AUTOSAR XML (schema 4-2-2)
package /STELLANTIS/EPT/ASWCs
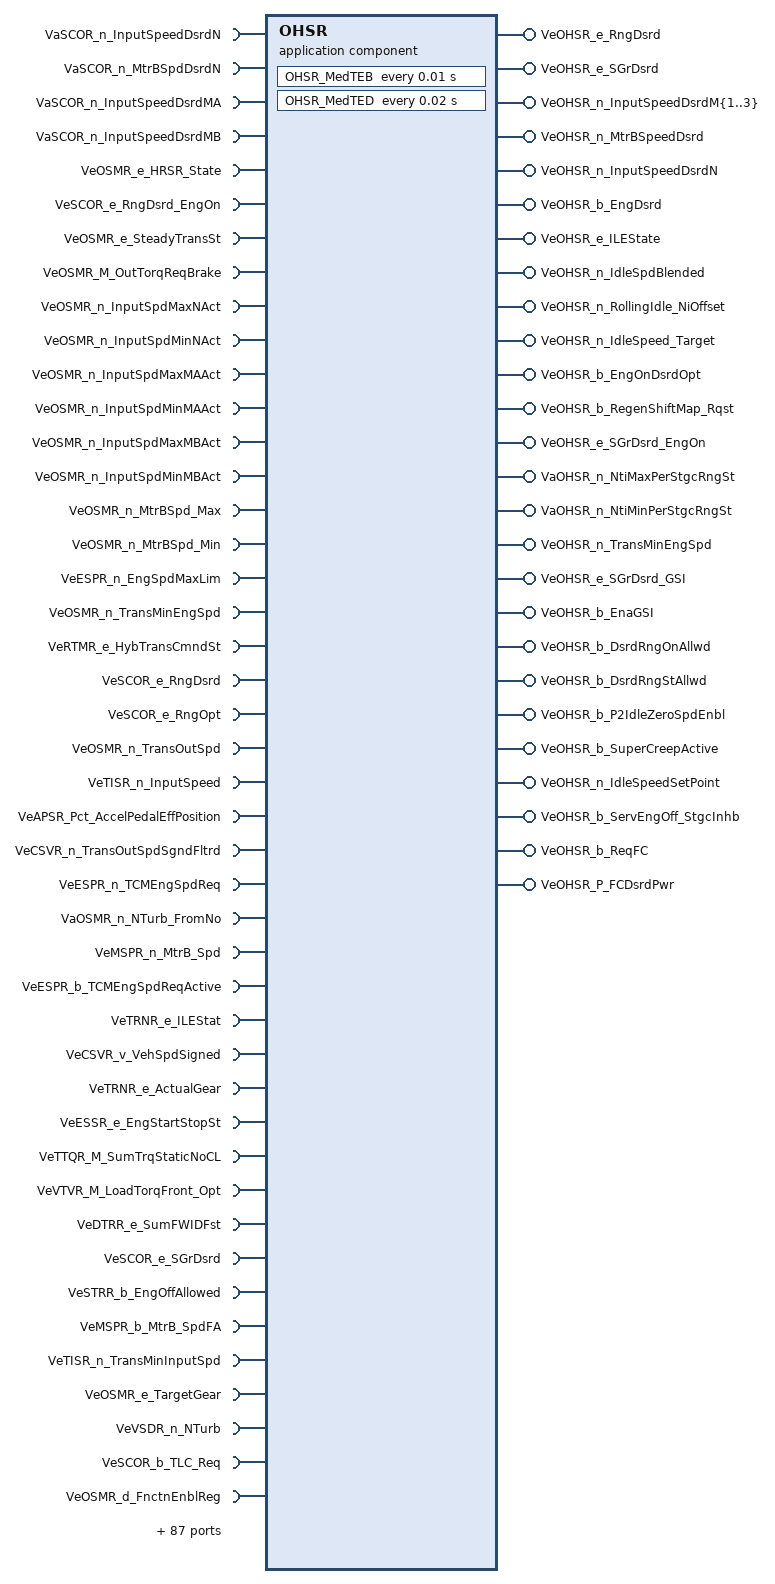
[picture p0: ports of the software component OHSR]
  application sw component type OHSR
    107 x require port:
      VaSCOR_n_InputSpeedDsrdN: nonqueued-receiver-com-spec{data-element=Value, init-value=9 x 0}, required-interface=VaSCOR_n_InputSpeedDsrdN
      VaSCOR_n_MtrBSpdDsrdN: nonqueued-receiver-com-spec{data-element=Value, init-value=9 x 0}, required-interface=VaSCOR_n_MtrBSpdDsrdN
      VaSCOR_n_InputSpeedDsrdMA: nonqueued-receiver-com-spec{data-element=Value, init-value=9 x 0}, required-interface=VaSCOR_n_InputSpeedDsrdMA
      VaSCOR_n_InputSpeedDsrdMB: nonqueued-receiver-com-spec{data-element=Value, init-value=9 x 0}, required-interface=VaSCOR_n_InputSpeedDsrdMB
      VeOSMR_e_HRSR_State: nonqueued-receiver-com-spec{data-element=Value, init-value=CeOSMR_e_N_State}, required-interface=VeOSMR_e_HRSR_State
      VeSCOR_e_RngDsrd_EngOn: nonqueued-receiver-com-spec{data-element=Value, init-value=CeSCOR_e_SG_Neutral}, required-interface=VeSCOR_e_RngDsrd_EngOn
      VeOSMR_e_SteadyTransSt: nonqueued-receiver-com-spec{data-element=Value, init-value=CeOSMR_e_TransSt_Drive}, required-interface=VeOSMR_e_SteadyTransSt
      VeOSMR_M_OutTorqReqBrake: nonqueued-receiver-com-spec{data-element=Value, init-value=0}, required-interface=VeOSMR_M_OutTorqReqBrake
      VeOSMR_n_InputSpdMaxNAct: nonqueued-receiver-com-spec{data-element=Value, init-value=0}, required-interface=VeOSMR_n_InputSpdMaxNAct
      VeOSMR_n_InputSpdMinNAct: nonqueued-receiver-com-spec{data-element=Value, init-value=0}, required-interface=VeOSMR_n_InputSpdMinNAct
      VeOSMR_n_InputSpdMaxMAAct: nonqueued-receiver-com-spec{data-element=Value, init-value=0}, required-interface=VeOSMR_n_InputSpdMaxMAAct
      VeOSMR_n_InputSpdMinMAAct: nonqueued-receiver-com-spec{data-element=Value, init-value=0}, required-interface=VeOSMR_n_InputSpdMinMAAct
      VeOSMR_n_InputSpdMaxMBAct: nonqueued-receiver-com-spec{data-element=Value, init-value=0}, required-interface=VeOSMR_n_InputSpdMaxMBAct
      VeOSMR_n_InputSpdMinMBAct: nonqueued-receiver-com-spec{data-element=Value, init-value=0}, required-interface=VeOSMR_n_InputSpdMinMBAct
      VeOSMR_n_MtrBSpd_Max: nonqueued-receiver-com-spec{data-element=Value, init-value=0}, required-interface=VeOSMR_n_MtrBSpd_Max
      VeOSMR_n_MtrBSpd_Min: nonqueued-receiver-com-spec{data-element=Value, init-value=0}, required-interface=VeOSMR_n_MtrBSpd_Min
      VeESPR_n_EngSpdMaxLim: nonqueued-receiver-com-spec{data-element=Value, init-value=0}, required-interface=VeESPR_n_EngSpdMaxLim
      VeOSMR_n_TransMinEngSpd: nonqueued-receiver-com-spec{data-element=Value, init-value=0}, required-interface=VeOSMR_n_TransMinEngSpd
      VeRTMR_e_HybTransCmndSt: nonqueued-receiver-com-spec{data-element=Value, init-value=CeOHSR_e_RngSel_N}, required-interface=VeRTMR_e_HybTransCmndSt
      VeSCOR_e_RngDsrd: nonqueued-receiver-com-spec{data-element=Value, init-value=CeSCOR_e_SG_Neutral}, required-interface=VeSCOR_e_RngDsrd
      VeSCOR_e_RngOpt: nonqueued-receiver-com-spec{data-element=Value, init-value=CeSCOR_e_SG_Neutral}, required-interface=VeSCOR_e_RngOpt
      VeOSMR_n_TransOutSpd: nonqueued-receiver-com-spec{data-element=Value, init-value=0}, required-interface=VeOSMR_n_TransOutSpd
      VeTISR_n_InputSpeed: nonqueued-receiver-com-spec{data-element=Value, init-value=0}, required-interface=VeTISR_n_InputSpeed
      VeAPSR_Pct_AccelPedalEffPosition: nonqueued-receiver-com-spec{data-element=Value, init-value=0}, required-interface=VeAPSR_Pct_AccelPedalEffPosition
      VeCSVR_n_TransOutSpdSgndFltrd: nonqueued-receiver-com-spec{data-element=Value, init-value=0}, required-interface=VeCSVR_n_TransOutSpdSgndFltrd
      VeESPR_n_TCMEngSpdReq: nonqueued-receiver-com-spec{data-element=Value, init-value=0}, required-interface=VeESPR_n_TCMEngSpdReq
      VaOSMR_n_NTurb_FromNo: nonqueued-receiver-com-spec{data-element=Value, init-value=9 x 0}, required-interface=VaOSMR_n_NTurb_FromNo
      VeMSPR_n_MtrB_Spd: nonqueued-receiver-com-spec{data-element=Value, init-value=0}, required-interface=VeMSPR_n_MtrB_Spd
      VeESPR_b_TCMEngSpdReqActive: nonqueued-receiver-com-spec{data-element=Value, init-value=0}, required-interface=VeESPR_b_TCMEngSpdReqActive
      VeTRNR_e_ILEStat: nonqueued-receiver-com-spec{data-element=Value, init-value=CeHCCR_e_ClInvalid}, required-interface=VeTRNR_e_ILEStat
      VeCSVR_v_VehSpdSigned: nonqueued-receiver-com-spec{data-element=Value, init-value=0}, required-interface=VeCSVR_v_VehSpdSigned
      VeTRNR_e_ActualGear: nonqueued-receiver-com-spec{data-element=Value, init-value=CeTRNR_e_Neutral}, required-interface=VeTRNR_e_ActualGear
      VeESSR_e_EngStartStopSt: nonqueued-receiver-com-spec{data-element=Value, init-value=CeESSR_e_EngOff}, required-interface=VeESSR_e_EngStartStopSt
      VeTTQR_M_SumTrqStaticNoCL: nonqueued-receiver-com-spec{data-element=Value, init-value=0}, required-interface=VeTTQR_M_SumTrqStaticNoCL
      VeVTVR_M_LoadTorqFront_Opt: nonqueued-receiver-com-spec{data-element=Value, init-value=0}, required-interface=VeVTVR_M_LoadTorqFront_Opt
      VeDTRR_e_SumFWIDFst: nonqueued-receiver-com-spec{data-element=Value, init-value=CeDTRR_e_Potential}, required-interface=VeDTRR_e_SumFWIDFst
      VeSCOR_e_SGrDsrd: nonqueued-receiver-com-spec{data-element=Value, init-value=CeSCOR_e_SG_1}, required-interface=VeSCOR_e_SGrDsrd
      VeSTRR_b_EngOffAllowed: nonqueued-receiver-com-spec{data-element=Value, init-value=0}, required-interface=VeSTRR_b_EngOffAllowed
      VeMSPR_b_MtrB_SpdFA: nonqueued-receiver-com-spec{data-element=Value, init-value=0}, required-interface=VeMSPR_b_MtrB_SpdFA
      VeTISR_n_TransMinInputSpd: nonqueued-receiver-com-spec{data-element=Value, init-value=0}, required-interface=VeTISR_n_TransMinInputSpd
      VeOSMR_e_TargetGear: nonqueued-receiver-com-spec{data-element=Value, init-value=CeTRNR_e_Neutral}, required-interface=VeOSMR_e_TargetGear
      VeVSDR_n_NTurb: nonqueued-receiver-com-spec{data-element=Value, init-value=0}, required-interface=VeVSDR_n_NTurb
      VeSCOR_b_TLC_Req: nonqueued-receiver-com-spec{data-element=Value, init-value=0}, required-interface=VeSCOR_b_TLC_Req
      VeOSMR_d_FnctnEnblReg: nonqueued-receiver-com-spec{data-element=Value, init-value=0}, required-interface=VeOSMR_d_FnctnEnblReg
      VeOSMR_e_ActualGear: nonqueued-receiver-com-spec{data-element=Value, init-value=CeTRNR_e_Neutral}, required-interface=VeOSMR_e_ActualGear
      VeSCOR_e_SGrDsrd_EngOn: variation-point={short-label=vpVeSCOR_e_SGrDsrd_EngOn, sw-syscond=1}, nonqueued-receiver-com-spec{data-element=Value, init-value=CeSCOR_e_SG_1}, required-interface=VeSCOR_e_SGrDsrd_EngOn
      VaOSMR_n_NtiMax_N: nonqueued-receiver-com-spec{data-element=Value, init-value=9 x 0}, required-interface=VaOSMR_n_NtiMax_N
      VaOSMR_n_NtiMax_MA: nonqueued-receiver-com-spec{data-element=Value, init-value=9 x 0}, required-interface=VaOSMR_n_NtiMax_MA
      VaOSMR_n_NtiMax_MB: nonqueued-receiver-com-spec{data-element=Value, init-value=9 x 0}, required-interface=VaOSMR_n_NtiMax_MB
      VaOSMR_n_NtiMax_Gr: nonqueued-receiver-com-spec{data-element=Value, init-value=9 x 0}, required-interface=VaOSMR_n_NtiMax_Gr
      VaOSMR_n_NtiMax_EVM: nonqueued-receiver-com-spec{data-element=Value, init-value=9 x 0}, required-interface=VaOSMR_n_NtiMax_EVM
      VaOSMR_n_NtiMax_EVN: nonqueued-receiver-com-spec{data-element=Value, init-value=9 x 0}, required-interface=VaOSMR_n_NtiMax_EVN
      VaOSMR_n_NtiMin_N: nonqueued-receiver-com-spec{data-element=Value, init-value=9 x 0}, required-interface=VaOSMR_n_NtiMin_N
      VaOSMR_n_NtiMin_MA: nonqueued-receiver-com-spec{data-element=Value, init-value=9 x 0}, required-interface=VaOSMR_n_NtiMin_MA
      VaOSMR_n_NtiMin_MB: nonqueued-receiver-com-spec{data-element=Value, init-value=9 x 0}, required-interface=VaOSMR_n_NtiMin_MB
      VaOSMR_n_NtiMin_Gr: nonqueued-receiver-com-spec{data-element=Value, init-value=9 x 0}, required-interface=VaOSMR_n_NtiMin_Gr
      VaOSMR_n_NtiMin_EVM: nonqueued-receiver-com-spec{data-element=Value, init-value=9 x 0}, required-interface=VaOSMR_n_NtiMin_EVM
      VaOSMR_n_NtiMin_EVN: nonqueued-receiver-com-spec{data-element=Value, init-value=9 x 0}, required-interface=VaOSMR_n_NtiMin_EVN
      VeHSER_e_RngSt: nonqueued-receiver-com-spec{data-element=Value, init-value=CeHSER_e_Init}, required-interface=VeHSER_e_RngSt
      VeHSER_e_HTDR_State: nonqueued-receiver-com-spec{data-element=Value, init-value=CeHSER_e_Neut_State}, required-interface=VeHSER_e_HTDR_State
      VeTFTR_T_TransOilTemp: nonqueued-receiver-com-spec{data-element=Value, init-value=0}, required-interface=VeTFTR_T_TransOilTemp
      VeSCOR_Pct_TtlPdlChange: nonqueued-receiver-com-spec{data-element=Value, init-value=0}, required-interface=VeSCOR_Pct_TtlPdlChange
      VeFWDR_e_Tcase_Stat: nonqueued-receiver-com-spec{data-element=Value, init-value=CeFWDR_e_ShiftINProg}, required-interface=VeFWDR_e_Tcase_Stat
      VeVTVR_e_TrqArb: nonqueued-receiver-com-spec{data-element=Value, init-value=CeWTAR_e_ECM_TorqReqst}, required-interface=VeVTVR_e_TrqArb
      VeTRNR_e_TargetGear: nonqueued-receiver-com-spec{data-element=Value, init-value=CeTRNR_e_Neutral}, required-interface=VeTRNR_e_TargetGear
      VeSCOR_b_DsrdRngStAllwd: nonqueued-receiver-com-spec{data-element=Value, init-value=0}, required-interface=VeSCOR_b_DsrdRngStAllwd
      VeESPR_n_EngSpdMinLim: nonqueued-receiver-com-spec{data-element=Value, init-value=0}, required-interface=VeESPR_n_EngSpdMinLim
      VaOSMR_d_FinalAllwdFxdGr: nonqueued-receiver-com-spec{data-element=Value, init-value=6 x 0}, required-interface=VaOSMR_d_FinalAllwdFxdGr
      VaOSMR_d_FinalAllwdDsrd: nonqueued-receiver-com-spec{data-element=Value, init-value=6 x 0}, required-interface=VaOSMR_d_FinalAllwdDsrd
      VeSCOR_b_DsrdRngOnAllwd: nonqueued-receiver-com-spec{data-element=Value, init-value=0}, required-interface=VeSCOR_b_DsrdRngOnAllwd
      VeOSMR_n_InputSpdMaxNTgt: nonqueued-receiver-com-spec{data-element=Value, init-value=0}, required-interface=VeOSMR_n_InputSpdMaxNTgt
      VeOSMR_n_InputSpdMinNTgt: nonqueued-receiver-com-spec{data-element=Value, init-value=0}, required-interface=VeOSMR_n_InputSpdMinNTgt
      VeOSMR_n_InputSpdMaxMATgt: nonqueued-receiver-com-spec{data-element=Value, init-value=0}, required-interface=VeOSMR_n_InputSpdMaxMATgt
      VeOSMR_n_InputSpdMinMATgt: nonqueued-receiver-com-spec{data-element=Value, init-value=0}, required-interface=VeOSMR_n_InputSpdMinMATgt
      VeOSMR_n_InputSpdMaxMBTgt: nonqueued-receiver-com-spec{data-element=Value, init-value=0}, required-interface=VeOSMR_n_InputSpdMaxMBTgt
      VeOSMR_n_InputSpdMinMBTgt: nonqueued-receiver-com-spec{data-element=Value, init-value=0}, required-interface=VeOSMR_n_InputSpdMinMBTgt
      VeRGNR_M_DrvIntndTotBrk_Stgc: nonqueued-receiver-com-spec{data-element=Value, init-value=0}, required-interface=VeRGNR_M_DrvIntndTotBrk_Stgc
      VeRTMR_e_ClutchLrnType: nonqueued-receiver-com-spec{data-element=Value, init-value=CeRTMR_e_Clutch_NoLrn}, required-interface=VeRTMR_e_ClutchLrnType
      VeMSPR_n_P2SpdControl_TgtSpd: nonqueued-receiver-com-spec{data-element=Value, init-value=0}, required-interface=VeMSPR_n_P2SpdControl_TgtSpd
      VeHSER_e_RngEqnSel: nonqueued-receiver-com-spec{data-element=Value, init-value=CeHSER_e_UseNeutralEqn}, required-interface=VeHSER_e_RngEqnSel
      VaOSMR_d_FinalAllwdOpt: nonqueued-receiver-com-spec{data-element=Value, init-value=6 x 0}, required-interface=VaOSMR_d_FinalAllwdOpt
      VeOSMR_b_EngOffAllwdOpt: nonqueued-receiver-com-spec{data-element=Value, init-value=0}, required-interface=VeOSMR_b_EngOffAllwdOpt
      VeCTCR_b_MinCreepEnable_Stgc: nonqueued-receiver-com-spec{data-element=Value, init-value=0}, required-interface=VeCTCR_b_MinCreepEnable_Stgc
      VeBRKR_b_ReqSSC_IdlDst: nonqueued-receiver-com-spec{data-element=Value, init-value=0}, required-interface=VeBRKR_b_ReqSSC_IdlDst
      VeEOCR_b_ColdCtrl_Raw: nonqueued-receiver-com-spec{data-element=Value, init-value=0}, required-interface=VeEOCR_b_ColdCtrl_Raw
      VeCSVR_n_PrimWhlSpdSigned: nonqueued-receiver-com-spec{data-element=Value, init-value=0}, required-interface=VeCSVR_n_PrimWhlSpdSigned
      VeTTQR_e_TCMTrqCntrlMdFst: nonqueued-receiver-com-spec{data-element=Value, init-value=CeTINR_e_None}, required-interface=VeTTQR_e_TCMTrqCntrlMdFst
      VaSCOR_n_C1SlipSpdDsrdN: nonqueued-receiver-com-spec{data-element=Value, init-value=9 x 0}, required-interface=VaSCOR_n_C1SlipSpdDsrdN
      VaSCOR_n_C2SlipSpdDsrdN: nonqueued-receiver-com-spec{data-element=Value, init-value=9 x 0}, required-interface=VaSCOR_n_C2SlipSpdDsrdN
      VeOSMR_d_ManualAllowedN: nonqueued-receiver-com-spec{data-element=Value, init-value=0}, required-interface=VeOSMR_d_ManualAllowedN
      VeOSMR_d_ManualAllowedMA: nonqueued-receiver-com-spec{data-element=Value, init-value=0}, required-interface=VeOSMR_d_ManualAllowedMA
      VeOSMR_d_ManualAllowedMB: nonqueued-receiver-com-spec{data-element=Value, init-value=0}, required-interface=VeOSMR_d_ManualAllowedMB
      VeRTMR_n_TransInputSpd: nonqueued-receiver-com-spec{data-element=Value, init-value=0}, required-interface=VeRTMR_n_TransInputSpd
      VeOSMR_b_ServEngOffReq_Actv: nonqueued-receiver-com-spec{data-element=Value, init-value=0}, required-interface=VeOSMR_b_ServEngOffReq_Actv
      VaSCOR_n_StgcNiMin_N: nonqueued-receiver-com-spec{data-element=Value, init-value=9 x 0}, required-interface=VaSCOR_n_StgcNiMin_N
      VaSCOR_n_StgcNiMin_MA: nonqueued-receiver-com-spec{data-element=Value, init-value=9 x 0}, required-interface=VaSCOR_n_StgcNiMin_MA
      VaSCOR_n_StgcNiMin_MB: nonqueued-receiver-com-spec{data-element=Value, init-value=9 x 0}, required-interface=VaSCOR_n_StgcNiMin_MB
      VeBPCR_Pct_HV_BatPackSOC_Arb: nonqueued-receiver-com-spec{data-element=Value, init-value=0}, required-interface=VeBPCR_Pct_HV_BatPackSOC_Arb
      VeBACR_Pct_TargetSOC_Stgc: nonqueued-receiver-com-spec{data-element=Value, init-value=0}, required-interface=VeBACR_Pct_TargetSOC_Stgc
      VaSCOR_P_EngPwrLoss_N: nonqueued-receiver-com-spec{data-element=Value, init-value=9 x 0}, required-interface=VaSCOR_P_EngPwrLoss_N
      VaSCOR_P_EngPwrLoss_MA: nonqueued-receiver-com-spec{data-element=Value, init-value=9 x 0}, required-interface=VaSCOR_P_EngPwrLoss_MA
      VaSCOR_P_EngPwrLoss_MB: nonqueued-receiver-com-spec{data-element=Value, init-value=9 x 0}, required-interface=VaSCOR_P_EngPwrLoss_MB
      VeICSR_M_EngCL: nonqueued-receiver-com-spec{data-element=Value, init-value=0}, required-interface=VeICSR_M_EngCL
      VeENGR_T_CatalystTemp: nonqueued-receiver-com-spec{data-element=Value, init-value=0}, required-interface=VeENGR_T_CatalystTemp
      VeOSMR_i_DrvPrg_AutoRevMaxType: nonqueued-receiver-com-spec{data-element=Value, init-value=0}, required-interface=VeOSMR_i_DrvPrg_AutoRevMaxType
      VeSCOR_b_ReqFC: nonqueued-receiver-com-spec{data-element=Value, init-value=0}, required-interface=VeSCOR_b_ReqFC
      VeSCOR_P_FCDsrdPwr: nonqueued-receiver-com-spec{data-element=Value, init-value=0}, required-interface=VeSCOR_P_FCDsrdPwr
    28 x provide port:
      VeOHSR_e_RngDsrd: nonqueued-sender-com-spec{data-element=Value, init-value=CeOHSR_e_RngSel_N}, provided-interface=VeOHSR_e_RngDsrd
      VeOHSR_e_SGrDsrd: nonqueued-sender-com-spec{data-element=Value, init-value=CeOHSR_e_SG_Reverse}, provided-interface=VeOHSR_e_SGrDsrd
      VeOHSR_n_InputSpeedDsrdM{1..3}: nonqueued-sender-com-spec{data-element=Value, init-value=0}, provided-interface=VeOHSR_n_InputSpeedDsrdM{1..3}
      VeOHSR_n_MtrBSpeedDsrd: nonqueued-sender-com-spec{data-element=Value, init-value=0}, provided-interface=VeOHSR_n_MtrBSpeedDsrd
      VeOHSR_n_InputSpeedDsrdN: nonqueued-sender-com-spec{data-element=Value, init-value=0}, provided-interface=VeOHSR_n_InputSpeedDsrdN
      VeOHSR_b_EngDsrd: nonqueued-sender-com-spec{data-element=Value, init-value=0}, provided-interface=VeOHSR_b_EngDsrd
      VeOHSR_e_ILEState: nonqueued-sender-com-spec{data-element=Value, init-value=CeOHSR_e_NeutralState}, provided-interface=VeOHSR_e_ILEState
      VeOHSR_n_IdleSpdBlended: nonqueued-sender-com-spec{data-element=Value, init-value=0}, provided-interface=VeOHSR_n_IdleSpdBlended
      VeOHSR_n_RollingIdle_NiOffset: nonqueued-sender-com-spec{data-element=Value, init-value=0}, provided-interface=VeOHSR_n_RollingIdle_NiOffset
      VeOHSR_n_IdleSpeed_Target: nonqueued-sender-com-spec{data-element=Value, init-value=0}, provided-interface=VeOHSR_n_IdleSpeed_Target
      VeOHSR_b_EngOnDsrdOpt: nonqueued-sender-com-spec{data-element=Value, init-value=0}, provided-interface=VeOHSR_b_EngOnDsrdOpt
      VeOHSR_b_RegenShiftMap_Rqst: nonqueued-sender-com-spec{data-element=Value, init-value=0}, provided-interface=VeOHSR_b_RegenShiftMap_Rqst
      VeOHSR_e_SGrDsrd_EngOn: nonqueued-sender-com-spec{data-element=Value, init-value=CeOHSR_e_SG_Reverse}, provided-interface=VeOHSR_e_SGrDsrd_EngOn
      VaOHSR_n_NtiMaxPerStgcRngSt: nonqueued-sender-com-spec{data-element=Value, init-value=6 x 0}, provided-interface=VaOHSR_n_NtiMaxPerStgcRngSt
      VaOHSR_n_NtiMinPerStgcRngSt: nonqueued-sender-com-spec{data-element=Value, init-value=6 x 0}, provided-interface=VaOHSR_n_NtiMinPerStgcRngSt
      VeOHSR_n_TransMinEngSpd: nonqueued-sender-com-spec{data-element=Value, init-value=0}, provided-interface=VeOHSR_n_TransMinEngSpd
      VeOHSR_e_SGrDsrd_GSI: nonqueued-sender-com-spec{data-element=Value, init-value=CeOHSR_e_SG_Reverse}, provided-interface=VeOHSR_e_SGrDsrd_GSI
      VeOHSR_b_EnaGSI: nonqueued-sender-com-spec{data-element=Value, init-value=0}, provided-interface=VeOHSR_b_EnaGSI
      VeOHSR_b_DsrdRngOnAllwd: nonqueued-sender-com-spec{data-element=Value, init-value=0}, provided-interface=VeOHSR_b_DsrdRngOnAllwd
      VeOHSR_b_DsrdRngStAllwd: nonqueued-sender-com-spec{data-element=Value, init-value=0}, provided-interface=VeOHSR_b_DsrdRngStAllwd
      VeOHSR_b_P2IdleZeroSpdEnbl: nonqueued-sender-com-spec{data-element=Value, init-value=0}, provided-interface=VeOHSR_b_P2IdleZeroSpdEnbl
      VeOHSR_b_SuperCreepActive: nonqueued-sender-com-spec{data-element=Value, init-value=0}, provided-interface=VeOHSR_b_SuperCreepActive
      VeOHSR_n_IdleSpeedSetPoint: nonqueued-sender-com-spec{data-element=Value, init-value=0}, provided-interface=VeOHSR_n_IdleSpeedSetPoint
      VeOHSR_b_ServEngOff_StgcInhb: nonqueued-sender-com-spec{data-element=Value, init-value=0}, provided-interface=VeOHSR_b_ServEngOff_StgcInhb
      VeOHSR_b_ReqFC: nonqueued-sender-com-spec{data-element=Value, init-value=0}, provided-interface=VeOHSR_b_ReqFC
      VeOHSR_P_FCDsrdPwr: nonqueued-sender-com-spec{data-element=Value, init-value=0}, provided-interface=VeOHSR_P_FCDsrdPwr
    24 x require port:
      KeOPTR_M_P2ZeroIdle_2Pdl_BrkTrq_LSP: parameter-require-com-spec{init-value=KeOPTR_M_P2ZeroIdle_2Pdl_BrkTrq_LSP_KeOPTR_M_P2ZeroIdle_2Pdl_BrkTrq_LSP:-50, parameter=KeOPTR_M_P2ZeroIdle_2Pdl_BrkTrq_LSP}, required-interface=KeOPTR_M_P2ZeroIdle_2Pdl_BrkTrq_LSP
      KeOPTR_M_P2ZeroIdle_2Pdl_BrkTrq_RSP: parameter-require-com-spec{init-value=KeOPTR_M_P2ZeroIdle_2Pdl_BrkTrq_RSP_KeOPTR_M_P2ZeroIdle_2Pdl_BrkTrq_RSP:-30, parameter=KeOPTR_M_P2ZeroIdle_2Pdl_BrkTrq_RSP}, required-interface=KeOPTR_M_P2ZeroIdle_2Pdl_BrkTrq_RSP
      KeOPTR_M_P2ZeroIdle_BrkTrqMin_RSP_OS: parameter-require-com-spec{init-value=KeOPTR_M_P2ZeroIdle_BrkTrqMin_RSP_OS_KeOPTR_M_P2ZeroIdle_BrkTrqMin_RSP_OS:30, parameter=KeOPTR_M_P2ZeroIdle_BrkTrqMin_RSP_OS}, required-interface=KeOPTR_M_P2ZeroIdle_BrkTrqMin_RSP_OS
      KeOPTR_Pct_P2ZeroIdle_2Pdl_Acl_LSP: parameter-require-com-spec{init-value=KeOPTR_Pct_P2ZeroIdle_2Pdl_Acl_LSP_KeOPTR_Pct_P2ZeroIdle_2Pdl_Acl_LSP:1, parameter=KeOPTR_Pct_P2ZeroIdle_2Pdl_Acl_LSP}, required-interface=KeOPTR_Pct_P2ZeroIdle_2Pdl_Acl_LSP
      KeOPTR_Pct_P2ZeroIdle_2Pdl_Acl_RSP: parameter-require-com-spec{init-value=KeOPTR_Pct_P2ZeroIdle_2Pdl_Acl_RSP_KeOPTR_Pct_P2ZeroIdle_2Pdl_Acl_RSP:0, parameter=KeOPTR_Pct_P2ZeroIdle_2Pdl_Acl_RSP}, required-interface=KeOPTR_Pct_P2ZeroIdle_2Pdl_Acl_RSP
      KeOPTR_n_P2Idle_ZeroRPM: parameter-require-com-spec{init-value=KeOPTR_n_P2Idle_ZeroRPM_KeOPTR_n_P2Idle_ZeroRPM:0, parameter=KeOPTR_n_P2Idle_ZeroRPM}, required-interface=KeOPTR_n_P2Idle_ZeroRPM
      KeOPTR_n_P2MinIdle_TransMinSpd_LSP: parameter-require-com-spec{init-value=KeOPTR_n_P2MinIdle_TransMinSpd_LSP_KeOPTR_n_P2MinIdle_TransMinSpd_LSP:0.25, parameter=KeOPTR_n_P2MinIdle_TransMinSpd_LSP}, required-interface=KeOPTR_n_P2MinIdle_TransMinSpd_LSP
      KeOPTR_n_P2MinIdle_TransMinSpd_RSP: parameter-require-com-spec{init-value=KeOPTR_n_P2MinIdle_TransMinSpd_RSP_KeOPTR_n_P2MinIdle_TransMinSpd_RSP:0.5, parameter=KeOPTR_n_P2MinIdle_TransMinSpd_RSP}, required-interface=KeOPTR_n_P2MinIdle_TransMinSpd_RSP
      KeOPTR_n_P2ZeroIdle_NoMax_LSP: parameter-require-com-spec{init-value=KeOPTR_n_P2ZeroIdle_NoMax_LSP_KeOPTR_n_P2ZeroIdle_NoMax_LSP:20, parameter=KeOPTR_n_P2ZeroIdle_NoMax_LSP}, required-interface=KeOPTR_n_P2ZeroIdle_NoMax_LSP
      KeOPTR_n_P2ZeroIdle_NoMax_RSP: parameter-require-com-spec{init-value=KeOPTR_n_P2ZeroIdle_NoMax_RSP_KeOPTR_n_P2ZeroIdle_NoMax_RSP:25, parameter=KeOPTR_n_P2ZeroIdle_NoMax_RSP}, required-interface=KeOPTR_n_P2ZeroIdle_NoMax_RSP
      KeOPTR_n_RGS_ActivationThreshold: parameter-require-com-spec{init-value=KeOPTR_n_RGS_ActivationThreshold_KeOPTR_n_RGS_ActivationThreshold:500, parameter=KeOPTR_n_RGS_ActivationThreshold}, required-interface=KeOPTR_n_RGS_ActivationThreshold
      KeOPTR_n_RGS_IdleSpd: parameter-require-com-spec{init-value=KeOPTR_n_RGS_IdleSpd_KeOPTR_n_RGS_IdleSpd:950, parameter=KeOPTR_n_RGS_IdleSpd}, required-interface=KeOPTR_n_RGS_IdleSpd
      KeOPTR_t_BrkTrq_TstDer_CutOffT: parameter-require-com-spec{init-value=KeOPTR_t_BrkTrq_TstDer_CutOffT_KeOPTR_t_BrkTrq_TstDer_CutOffT:0.100000001490116, parameter=KeOPTR_t_BrkTrq_TstDer_CutOffT}, required-interface=KeOPTR_t_BrkTrq_TstDer_CutOffT
      KeOPTR_t_DelayTimeToggle: parameter-require-com-spec{init-value=KeOPTR_t_DelayTimeToggle_KeOPTR_t_DelayTimeToggle:10, parameter=KeOPTR_t_DelayTimeToggle}, required-interface=KeOPTR_t_DelayTimeToggle
      KeOPTR_t_RGS_Delay: parameter-require-com-spec{init-value=KeOPTR_t_RGS_Delay_KeOPTR_t_RGS_Delay:1, parameter=KeOPTR_t_RGS_Delay}, required-interface=KeOPTR_t_RGS_Delay
      KeOPTR_t_RGS_DelayTimeNTurb: parameter-require-com-spec{init-value=KeOPTR_t_RGS_DelayTimeNTurb_KeOPTR_t_RGS_DelayTimeNTurb:5, parameter=KeOPTR_t_RGS_DelayTimeNTurb}, required-interface=KeOPTR_t_RGS_DelayTimeNTurb
      KaOPTR_b_RGS_Gears_Sel: parameter-require-com-spec{init-value=KaOPTR_b_RGS_Gears_Sel_KaOPTR_b_RGS_Gears_Sel:[KaOPTR_b_RGS_Gears_Sel_KaOPTR_b_RGS_Gears_Sel_rt_Array_Boolean_13_1:0, KaOPTR_b_RGS_Gears_Sel_KaOPTR_b_RGS_Gears_Sel_rt_Array_Boolean_13_2:0, KaOPTR_b_RGS_Gears_Sel_KaOPTR_b_RGS_Gears_Sel_rt_Array_Boolean_13_3:0, KaOPTR_b_RGS_Gears_Sel_KaOPTR_b_RGS_Gears_Sel_rt_Array_Boolean_13_4:0, KaOPTR_b_RGS_Gears_Sel_KaOPTR_b_RGS_Gears_Sel_rt_Array_Boolean_13_5:0, KaOPTR_b_RGS_Gears_Sel_KaOPTR_b_RGS_Gears_Sel_rt_Array_Boolean_13_6:0, KaOPTR_b_RGS_Gears_Sel_KaOPTR_b_RGS_Gears_Sel_rt_Array_Boolean_13_7:0, KaOPTR_b_RGS_Gears_Sel_KaOPTR_b_RGS_Gears_Sel_rt_Array_Boolean_13_8:0, KaOPTR_b_RGS_Gears_Sel_KaOPTR_b_RGS_Gears_Sel_rt_Array_Boolean_13_9:0, KaOPTR_b_RGS_Gears_Sel_KaOPTR_b_RGS_Gears_Sel_rt_Array_Boolean_13_10:0, KaOPTR_b_RGS_Gears_Sel_KaOPTR_b_RGS_Gears_Sel_rt_Array_Boolean_13_11:0, KaOPTR_b_RGS_Gears_Sel_KaOPTR_b_RGS_Gears_Sel_rt_Array_Boolean_13_12:0, KaOPTR_b_RGS_Gears_Sel_KaOPTR_b_RGS_Gears_Sel_rt_Array_Boolean_13_13:0], parameter=KaOPTR_b_RGS_Gears_Sel}, required-interface=KaOPTR_b_RGS_Gears_Sel
      KaOPTR_b_ZeroRPMAllowPRNDL: parameter-require-com-spec{init-value=KaOPTR_b_ZeroRPMAllowPRNDL_KaOPTR_b_ZeroRPMAllowPRNDL:[KaOPTR_b_ZeroRPMAllowPRNDL_KaOPTR_b_ZeroRPMAllowPRNDL_rt_Array_Boolean_4_1:0, KaOPTR_b_ZeroRPMAllowPRNDL_KaOPTR_b_ZeroRPMAllowPRNDL_rt_Array_Boolean_4_2:0, KaOPTR_b_ZeroRPMAllowPRNDL_KaOPTR_b_ZeroRPMAllowPRNDL_rt_Array_Boolean_4_3:0, KaOPTR_b_ZeroRPMAllowPRNDL_KaOPTR_b_ZeroRPMAllowPRNDL_rt_Array_Boolean_4_4:0], parameter=KaOPTR_b_ZeroRPMAllowPRNDL}, required-interface=KaOPTR_b_ZeroRPMAllowPRNDL
      KaOPTR_b_ZeroRPMAllowTCase: parameter-require-com-spec{init-value=KaOPTR_b_ZeroRPMAllowTCase_KaOPTR_b_ZeroRPMAllowTCase:[KaOPTR_b_ZeroRPMAllowTCase_KaOPTR_b_ZeroRPMAllowTCase_rt_Array_Boolean_8_1:1, KaOPTR_b_ZeroRPMAllowTCase_KaOPTR_b_ZeroRPMAllowTCase_rt_Array_Boolean_8_2:1, KaOPTR_b_ZeroRPMAllowTCase_KaOPTR_b_ZeroRPMAllowTCase_rt_Array_Boolean_8_3:1, KaOPTR_b_ZeroRPMAllowTCase_KaOPTR_b_ZeroRPMAllowTCase_rt_Array_Boolean_8_4:1, KaOPTR_b_ZeroRPMAllowTCase_KaOPTR_b_ZeroRPMAllowTCase_rt_Array_Boolean_8_5:1, KaOPTR_b_ZeroRPMAllowTCase_KaOPTR_b_ZeroRPMAllowTCase_rt_Array_Boolean_8_6:1, KaOPTR_b_ZeroRPMAllowTCase_KaOPTR_b_ZeroRPMAllowTCase_rt_Array_Boolean_8_7:1, KaOPTR_b_ZeroRPMAllowTCase_KaOPTR_b_ZeroRPMAllowTCase_rt_Array_Boolean_8_8:1], parameter=KaOPTR_b_ZeroRPMAllowTCase}, required-interface=KaOPTR_b_ZeroRPMAllowTCase
      KeOPTR_b_RGS_Threshold_Disable: parameter-require-com-spec{init-value=KeOPTR_b_RGS_Threshold_Disable_KeOPTR_b_RGS_Threshold_Disable:0, parameter=KeOPTR_b_RGS_Threshold_Disable}, required-interface=KeOPTR_b_RGS_Threshold_Disable
      KtOPTR_n_P2IdleSpd: parameter-require-com-spec{init-value=10 x 720, parameter=KtOPTR_n_P2IdleSpd}, required-interface=KtOPTR_n_P2IdleSpd
      KxOPTR_n_P2IdleSpd: parameter-require-com-spec{init-value=[-3.3199999332428 0 0.670000016689301 0.839999973773956 1 1.27999997138977 1.66999995708466 2.09999990463257 3.14000010490417 4.71000003814697], parameter=KxOPTR_n_P2IdleSpd}, required-interface=KxOPTR_n_P2IdleSpd
      KtOPTR_M_P2ZeroIdle_BrkTrqThres: parameter-require-com-spec{init-value=[-100 -150 -250 -400 -500 -550], parameter=KtOPTR_M_P2ZeroIdle_BrkTrqThres}, required-interface=KtOPTR_M_P2ZeroIdle_BrkTrqThres
      KxOPTR_M_P2ZeroIdle_BrkTrqThres: parameter-require-com-spec{init-value=[0 100 200 500 1000 1500], parameter=KxOPTR_M_P2ZeroIdle_BrkTrqThres}, required-interface=KxOPTR_M_P2ZeroIdle_BrkTrqThres
    behavior IB_OHSR: data-type-mapping=msADTtoIDTMapping, handle-termination-and-restart=NO-SUPPORT, included-data-type-set=data-type=TeOHSR_e_ActActionBl
      timing event Event_MedTEB: start-on-event=OHSR_MedTEB, period=0.01
      timing event Event_MedTED: start-on-event=OHSR_MedTED, period=0.02
      init event Event_OHSR_ac_Init: start-on-event=OHSR_ac_Init
      init event Event_PwrOn: start-on-event=OHSR_PwrOn
      explicit-inter-runnable-variables:
        17 x data, all with sw-calibration-access=READ-ONLY:
          DsrdRngSt_write_IRV: category=VALUE, type=TeOHSR_e_RngSel, init-value=CeOHSR_e_RngSel_N
          ShftEfftRdctn_write_IRV: category=VALUE, type=Boolean, init-value=0
          ShftEfft_N4H_write_IRV: category=VALUE, type=Boolean, init-value=0
          NTurb_Virt_write_IRV: category=VALUE, type=Float, init-value=0
          VeOHSR_e_ILEState_write_IRV: category=VALUE, type=TeOHSR_e_VLE_DriveStat, init-value=CeOHSR_e_NeutralState
          VeOHSR_n_IdleSpdBlended_write_IRV: category=VALUE, type=Float, init-value=0
          Nti_Max_write_IRV: category=ARRAY, type=rt_Array_Float_54, init-value=54 x 0
          Nti_Min_write_IRV: category=ARRAY, type=rt_Array_Float_54, init-value=54 x 0
          ShiftToN_write_IRV: category=VALUE, type=Boolean, init-value=0
          TransMin_write_IRV: category=VALUE, type=Float, init-value=0
          S2H_write_IRV: category=VALUE, type=Boolean, init-value=0
          PS_write_IRV: category=VALUE, type=Boolean, init-value=0
          EnblTCMReqL_write_IRV: category=VALUE, type=Boolean, init-value=0
          NTurb_ActGr_write_IRV: category=VALUE, type=Float, init-value=0
          dSOC_write_IRV: category=VALUE, type=Float, init-value=0
          StgcMaxGear_NVH_write_IRV: category=ARRAY, type=rt_Array_TeSCOR_e_OptGear_SG_4, init-value=[CeSCOR_e_SG_1, CeSCOR_e_SG_1, CeSCOR_e_SG_1, CeSCOR_e_SG_1]
          RegenShiftMapRqst_write_IRV: category=VALUE, type=Boolean, init-value=0
      4 x runnable:
        OHSR_ac_Init
          data-send-points:
            7 x access:
              OUT_VeOHSR_e_RngDsrd_Value: accessed-variable=VeOHSR_e_RngDsrd.Value
              OUT_VeOHSR_e_SGrDsrd_Value: accessed-variable=VeOHSR_e_SGrDsrd.Value
              OUT_VeOHSR_e_ILEState_Value: accessed-variable=VeOHSR_e_ILEState.Value
              OUT_VeOHSR_e_SGrDsrd_EngOn_Value: accessed-variable=VeOHSR_e_SGrDsrd_EngOn.Value
              OUT_VaOHSR_n_NtiMaxPerStgcRngSt_Value: accessed-variable=VaOHSR_n_NtiMaxPerStgcRngSt.Value
              OUT_VaOHSR_n_NtiMinPerStgcRngSt_Value: accessed-variable=VaOHSR_n_NtiMinPerStgcRngSt.Value
              OUT_VeOHSR_e_SGrDsrd_GSI_Value: accessed-variable=VeOHSR_e_SGrDsrd_GSI.Value
        OHSR_PwrOn
          data-send-points:
            28 x access:
              OUT_VeOHSR_b_EngOnDsrdOpt_Value: accessed-variable=VeOHSR_b_EngOnDsrdOpt.Value
              OUT_VeOHSR_n_InputSpeedDsrdM3_Value: accessed-variable=VeOHSR_n_InputSpeedDsrdM3.Value
              OUT_VeOHSR_n_MtrBSpeedDsrd_Value: accessed-variable=VeOHSR_n_MtrBSpeedDsrd.Value
              OUT_VeOHSR_e_SGrDsrd_Value: accessed-variable=VeOHSR_e_SGrDsrd.Value
              OUT_VeOHSR_n_TransMinEngSpd_Value: accessed-variable=VeOHSR_n_TransMinEngSpd.Value
              OUT_VeOHSR_n_InputSpeedDsrdM1_Value: accessed-variable=VeOHSR_n_InputSpeedDsrdM1.Value
              OUT_VeOHSR_e_SGrDsrd_EngOn_Value: accessed-variable=VeOHSR_e_SGrDsrd_EngOn.Value
              OUT_VeOHSR_n_InputSpeedDsrdM2_Value: accessed-variable=VeOHSR_n_InputSpeedDsrdM2.Value
              OUT_VeOHSR_b_EngDsrd_Value: accessed-variable=VeOHSR_b_EngDsrd.Value
              OUT_VeOHSR_n_InputSpeedDsrdN_Value: accessed-variable=VeOHSR_n_InputSpeedDsrdN.Value
              OUT_VeOHSR_e_RngDsrd_Value: accessed-variable=VeOHSR_e_RngDsrd.Value
              OUT_VeOHSR_n_RollingIdle_NiOffset_Value: accessed-variable=VeOHSR_n_RollingIdle_NiOffset.Value
              OUT_VeOHSR_b_RegenShiftMap_Rqst_Value: accessed-variable=VeOHSR_b_RegenShiftMap_Rqst.Value
              OUT_VeOHSR_e_ILEState_Value: accessed-variable=VeOHSR_e_ILEState.Value
              OUT_VeOHSR_n_IdleSpdBlended_Value: accessed-variable=VeOHSR_n_IdleSpdBlended.Value
              OUT_VeOHSR_n_IdleSpeed_Target_Value: accessed-variable=VeOHSR_n_IdleSpeed_Target.Value
              OUT_VaOHSR_n_NtiMaxPerStgcRngSt_Value: accessed-variable=VaOHSR_n_NtiMaxPerStgcRngSt.Value
              OUT_VaOHSR_n_NtiMinPerStgcRngSt_Value: accessed-variable=VaOHSR_n_NtiMinPerStgcRngSt.Value
              OUT_VeOHSR_e_SGrDsrd_GSI_Value: accessed-variable=VeOHSR_e_SGrDsrd_GSI.Value
              OUT_VeOHSR_b_EnaGSI_Value: accessed-variable=VeOHSR_b_EnaGSI.Value
              OUT_VeOHSR_b_DsrdRngOnAllwd_Value: accessed-variable=VeOHSR_b_DsrdRngOnAllwd.Value
              OUT_VeOHSR_b_DsrdRngStAllwd_Value: accessed-variable=VeOHSR_b_DsrdRngStAllwd.Value
              OUT_VeOHSR_b_P2IdleZeroSpdEnbl_Value: accessed-variable=VeOHSR_b_P2IdleZeroSpdEnbl.Value
              OUT_VeOHSR_b_SuperCreepActive_Value: accessed-variable=VeOHSR_b_SuperCreepActive.Value
              OUT_VeOHSR_n_IdleSpeedSetPoint_Value: accessed-variable=VeOHSR_n_IdleSpeedSetPoint.Value
              OUT_VeOHSR_b_ServEngOff_StgcInhb_Value: accessed-variable=VeOHSR_b_ServEngOff_StgcInhb.Value
              OUT_VeOHSR_P_FCDsrdPwr_Value: accessed-variable=VeOHSR_P_FCDsrdPwr.Value
              OUT_VeOHSR_b_ReqFC_Value: accessed-variable=VeOHSR_b_ReqFC.Value
          written-local-variables:
            17 x access:
              WV_DsrdRngSt_write_IRV: accessed-variable=DsrdRngSt_write_IRV
              WV_EnblTCMReqL_write_IRV: accessed-variable=EnblTCMReqL_write_IRV
              WV_NTurb_ActGr_write_IRV: accessed-variable=NTurb_ActGr_write_IRV
              WV_NTurb_Virt_write_IRV: accessed-variable=NTurb_Virt_write_IRV
              WV_Nti_Max_write_IRV: accessed-variable=Nti_Max_write_IRV
              WV_Nti_Min_write_IRV: accessed-variable=Nti_Min_write_IRV
              WV_PS_write_IRV: accessed-variable=PS_write_IRV
              WV_RegenShiftMapRqst_write_IRV: accessed-variable=RegenShiftMapRqst_write_IRV
              WV_S2H_write_IRV: accessed-variable=S2H_write_IRV
              WV_ShftEfftRdctn_write_IRV: accessed-variable=ShftEfftRdctn_write_IRV
              WV_ShftEfft_N4H_write_IRV: accessed-variable=ShftEfft_N4H_write_IRV
              WV_ShiftToN_write_IRV: accessed-variable=ShiftToN_write_IRV
              WV_StgcMaxGear_NVH_write_IRV: accessed-variable=StgcMaxGear_NVH_write_IRV
              WV_TransMin_write_IRV: accessed-variable=TransMin_write_IRV
              WV_VeOHSR_e_ILEState_write_IRV: accessed-variable=VeOHSR_e_ILEState_write_IRV
              WV_VeOHSR_n_IdleSpdBlended_write_IRV: accessed-variable=VeOHSR_n_IdleSpdBlended_write_IRV
              WV_dSOC_write_IRV: accessed-variable=dSOC_write_IRV
        OHSR_MedTEB
          data-receive-point-by-arguments:
            53 x access:
              IN_VaOSMR_n_NTurb_FromNo_Value: accessed-variable=VaOSMR_n_NTurb_FromNo.Value
              IN_VaOSMR_n_NtiMax_EVM_Value: accessed-variable=VaOSMR_n_NtiMax_EVM.Value
              IN_VaOSMR_n_NtiMax_EVN_Value: accessed-variable=VaOSMR_n_NtiMax_EVN.Value
              IN_VaOSMR_n_NtiMax_Gr_Value: accessed-variable=VaOSMR_n_NtiMax_Gr.Value
              IN_VaOSMR_n_NtiMax_MA_Value: accessed-variable=VaOSMR_n_NtiMax_MA.Value
              IN_VaOSMR_n_NtiMax_MB_Value: accessed-variable=VaOSMR_n_NtiMax_MB.Value
              IN_VaOSMR_n_NtiMax_N_Value: accessed-variable=VaOSMR_n_NtiMax_N.Value
              IN_VaOSMR_n_NtiMin_EVM_Value: accessed-variable=VaOSMR_n_NtiMin_EVM.Value
              IN_VaOSMR_n_NtiMin_EVN_Value: accessed-variable=VaOSMR_n_NtiMin_EVN.Value
              IN_VaOSMR_n_NtiMin_Gr_Value: accessed-variable=VaOSMR_n_NtiMin_Gr.Value
              IN_VaOSMR_n_NtiMin_MA_Value: accessed-variable=VaOSMR_n_NtiMin_MA.Value
              IN_VaOSMR_n_NtiMin_MB_Value: accessed-variable=VaOSMR_n_NtiMin_MB.Value
              IN_VaOSMR_n_NtiMin_N_Value: accessed-variable=VaOSMR_n_NtiMin_N.Value
              IN_VaSCOR_n_InputSpeedDsrdMA_Value: accessed-variable=VaSCOR_n_InputSpeedDsrdMA.Value
              IN_VaSCOR_n_InputSpeedDsrdMB_Value: accessed-variable=VaSCOR_n_InputSpeedDsrdMB.Value
              IN_VeAPSR_Pct_AccelPedalEffPosition_Value: accessed-variable=VeAPSR_Pct_AccelPedalEffPosition.Value
              IN_VeBACR_Pct_TargetSOC_Stgc_Value: accessed-variable=VeBACR_Pct_TargetSOC_Stgc.Value
              IN_VeBPCR_Pct_HV_BatPackSOC_Arb_Value: accessed-variable=VeBPCR_Pct_HV_BatPackSOC_Arb.Value
              IN_VeBRKR_b_ReqSSC_IdlDst_Value: accessed-variable=VeBRKR_b_ReqSSC_IdlDst.Value
              IN_VeCSVR_n_PrimWhlSpdSigned_Value: accessed-variable=VeCSVR_n_PrimWhlSpdSigned.Value
              IN_VeCSVR_n_TransOutSpdSgndFltrd_Value: accessed-variable=VeCSVR_n_TransOutSpdSgndFltrd.Value
              IN_VeCSVR_v_VehSpdSigned_Value: accessed-variable=VeCSVR_v_VehSpdSigned.Value
              IN_VeCTCR_b_MinCreepEnable_Stgc_Value: accessed-variable=VeCTCR_b_MinCreepEnable_Stgc.Value
              IN_VeDTRR_e_SumFWIDFst_Value: accessed-variable=VeDTRR_e_SumFWIDFst.Value
              IN_VeEOCR_b_ColdCtrl_Raw_Value: accessed-variable=VeEOCR_b_ColdCtrl_Raw.Value
              IN_VeESSR_e_EngStartStopSt_Value: accessed-variable=VeESSR_e_EngStartStopSt.Value
              IN_VeFWDR_e_Tcase_Stat_Value: accessed-variable=VeFWDR_e_Tcase_Stat.Value
              IN_VeHSER_e_HTDR_State_Value: accessed-variable=VeHSER_e_HTDR_State.Value
              IN_VeHSER_e_RngEqnSel_Value: accessed-variable=VeHSER_e_RngEqnSel.Value
              IN_VeHSER_e_RngSt_Value: accessed-variable=VeHSER_e_RngSt.Value
              IN_VeICSR_M_EngCL_Value: accessed-variable=VeICSR_M_EngCL.Value
              IN_VeMSPR_b_MtrB_SpdFA_Value: accessed-variable=VeMSPR_b_MtrB_SpdFA.Value
              IN_VeMSPR_n_MtrB_Spd_Value: accessed-variable=VeMSPR_n_MtrB_Spd.Value
              IN_VeMSPR_n_P2SpdControl_TgtSpd_Value: accessed-variable=VeMSPR_n_P2SpdControl_TgtSpd.Value
              IN_VeOSMR_M_OutTorqReqBrake_Value: accessed-variable=VeOSMR_M_OutTorqReqBrake.Value
              IN_VeOSMR_d_FnctnEnblReg_Value: accessed-variable=VeOSMR_d_FnctnEnblReg.Value
              IN_VeOSMR_e_ActualGear_Value: accessed-variable=VeOSMR_e_ActualGear.Value
              IN_VeOSMR_e_HRSR_State_Value: accessed-variable=VeOSMR_e_HRSR_State.Value
              IN_VeOSMR_e_SteadyTransSt_Value: accessed-variable=VeOSMR_e_SteadyTransSt.Value
              IN_VeOSMR_e_TargetGear_Value: accessed-variable=VeOSMR_e_TargetGear.Value
              IN_VeOSMR_n_TransMinEngSpd_Value: accessed-variable=VeOSMR_n_TransMinEngSpd.Value
              IN_VeRGNR_M_DrvIntndTotBrk_Stgc_Value: accessed-variable=VeRGNR_M_DrvIntndTotBrk_Stgc.Value
              IN_VeTFTR_T_TransOilTemp_Value: accessed-variable=VeTFTR_T_TransOilTemp.Value
              IN_VeTISR_n_InputSpeed_Value: accessed-variable=VeTISR_n_InputSpeed.Value
              IN_VeTISR_n_TransMinInputSpd_Value: accessed-variable=VeTISR_n_TransMinInputSpd.Value
              IN_VeTRNR_e_ActualGear_Value: accessed-variable=VeTRNR_e_ActualGear.Value
              IN_VeTRNR_e_ILEStat_Value: accessed-variable=VeTRNR_e_ILEStat.Value
              IN_VeTRNR_e_TargetGear_Value: accessed-variable=VeTRNR_e_TargetGear.Value
              IN_VeTTQR_M_SumTrqStaticNoCL_Value: accessed-variable=VeTTQR_M_SumTrqStaticNoCL.Value
              IN_VeTTQR_e_TCMTrqCntrlMdFst_Value: accessed-variable=VeTTQR_e_TCMTrqCntrlMdFst.Value
              IN_VeVSDR_n_NTurb_Value: accessed-variable=VeVSDR_n_NTurb.Value
              IN_VeVTVR_M_LoadTorqFront_Opt_Value: accessed-variable=VeVTVR_M_LoadTorqFront_Opt.Value
              IN_VeVTVR_e_TrqArb_Value: accessed-variable=VeVTVR_e_TrqArb.Value
          data-send-points:
            7 x access:
              OUT_VeOHSR_e_ILEState_Value: accessed-variable=VeOHSR_e_ILEState.Value
              OUT_VeOHSR_n_IdleSpdBlended_Value: accessed-variable=VeOHSR_n_IdleSpdBlended.Value
              OUT_VeOHSR_n_RollingIdle_NiOffset_Value: accessed-variable=VeOHSR_n_RollingIdle_NiOffset.Value
              OUT_VeOHSR_n_IdleSpeed_Target_Value: accessed-variable=VeOHSR_n_IdleSpeed_Target.Value
              OUT_VeOHSR_b_P2IdleZeroSpdEnbl_Value: accessed-variable=VeOHSR_b_P2IdleZeroSpdEnbl.Value
              OUT_VeOHSR_b_SuperCreepActive_Value: accessed-variable=VeOHSR_b_SuperCreepActive.Value
              OUT_VeOHSR_n_IdleSpeedSetPoint_Value: accessed-variable=VeOHSR_n_IdleSpeedSetPoint.Value
          24 x parameter access:
            CALPRM_KaOPTR_b_RGS_Gears_Sel_KaOPTR_b_RGS_Gears_Sel: accessed-parameter=KaOPTR_b_RGS_Gears_Sel.KaOPTR_b_RGS_Gears_Sel
            CALPRM_KaOPTR_b_ZeroRPMAllowPRNDL_KaOPTR_b_ZeroRPMAllowPRNDL: accessed-parameter=KaOPTR_b_ZeroRPMAllowPRNDL.KaOPTR_b_ZeroRPMAllowPRNDL
            CALPRM_KaOPTR_b_ZeroRPMAllowTCase_KaOPTR_b_ZeroRPMAllowTCase: accessed-parameter=KaOPTR_b_ZeroRPMAllowTCase.KaOPTR_b_ZeroRPMAllowTCase
            CALPRM_KeOPTR_M_P2ZeroIdle_2Pdl_BrkTrq_LSP_KeOPTR_M_P2ZeroIdle_2Pdl_BrkTrq_LSP: accessed-parameter=KeOPTR_M_P2ZeroIdle_2Pdl_BrkTrq_LSP.KeOPTR_M_P2ZeroIdle_2Pdl_BrkTrq_LSP
            CALPRM_KeOPTR_M_P2ZeroIdle_2Pdl_BrkTrq_RSP_KeOPTR_M_P2ZeroIdle_2Pdl_BrkTrq_RSP: accessed-parameter=KeOPTR_M_P2ZeroIdle_2Pdl_BrkTrq_RSP.KeOPTR_M_P2ZeroIdle_2Pdl_BrkTrq_RSP
            CALPRM_KeOPTR_M_P2ZeroIdle_BrkTrqMin_RSP_OS_KeOPTR_M_P2ZeroIdle_BrkTrqMin_RSP_OS: accessed-parameter=KeOPTR_M_P2ZeroIdle_BrkTrqMin_RSP_OS.KeOPTR_M_P2ZeroIdle_BrkTrqMin_RSP_OS
            CALPRM_KeOPTR_Pct_P2ZeroIdle_2Pdl_Acl_LSP_KeOPTR_Pct_P2ZeroIdle_2Pdl_Acl_LSP: accessed-parameter=KeOPTR_Pct_P2ZeroIdle_2Pdl_Acl_LSP.KeOPTR_Pct_P2ZeroIdle_2Pdl_Acl_LSP
            CALPRM_KeOPTR_Pct_P2ZeroIdle_2Pdl_Acl_RSP_KeOPTR_Pct_P2ZeroIdle_2Pdl_Acl_RSP: accessed-parameter=KeOPTR_Pct_P2ZeroIdle_2Pdl_Acl_RSP.KeOPTR_Pct_P2ZeroIdle_2Pdl_Acl_RSP
            CALPRM_KeOPTR_b_RGS_Threshold_Disable_KeOPTR_b_RGS_Threshold_Disable: accessed-parameter=KeOPTR_b_RGS_Threshold_Disable.KeOPTR_b_RGS_Threshold_Disable
            CALPRM_KeOPTR_n_P2Idle_ZeroRPM_KeOPTR_n_P2Idle_ZeroRPM: accessed-parameter=KeOPTR_n_P2Idle_ZeroRPM.KeOPTR_n_P2Idle_ZeroRPM
            CALPRM_KeOPTR_n_P2MinIdle_TransMinSpd_LSP_KeOPTR_n_P2MinIdle_TransMinSpd_LSP: accessed-parameter=KeOPTR_n_P2MinIdle_TransMinSpd_LSP.KeOPTR_n_P2MinIdle_TransMinSpd_LSP
            CALPRM_KeOPTR_n_P2MinIdle_TransMinSpd_RSP_KeOPTR_n_P2MinIdle_TransMinSpd_RSP: accessed-parameter=KeOPTR_n_P2MinIdle_TransMinSpd_RSP.KeOPTR_n_P2MinIdle_TransMinSpd_RSP
            CALPRM_KeOPTR_n_P2ZeroIdle_NoMax_LSP_KeOPTR_n_P2ZeroIdle_NoMax_LSP: accessed-parameter=KeOPTR_n_P2ZeroIdle_NoMax_LSP.KeOPTR_n_P2ZeroIdle_NoMax_LSP
            CALPRM_KeOPTR_n_P2ZeroIdle_NoMax_RSP_KeOPTR_n_P2ZeroIdle_NoMax_RSP: accessed-parameter=KeOPTR_n_P2ZeroIdle_NoMax_RSP.KeOPTR_n_P2ZeroIdle_NoMax_RSP
            CALPRM_KeOPTR_n_RGS_ActivationThreshold_KeOPTR_n_RGS_ActivationThreshold: accessed-parameter=KeOPTR_n_RGS_ActivationThreshold.KeOPTR_n_RGS_ActivationThreshold
            CALPRM_KeOPTR_n_RGS_IdleSpd_KeOPTR_n_RGS_IdleSpd: accessed-parameter=KeOPTR_n_RGS_IdleSpd.KeOPTR_n_RGS_IdleSpd
            CALPRM_KeOPTR_t_BrkTrq_TstDer_CutOffT_KeOPTR_t_BrkTrq_TstDer_CutOffT: accessed-parameter=KeOPTR_t_BrkTrq_TstDer_CutOffT.KeOPTR_t_BrkTrq_TstDer_CutOffT
            CALPRM_KeOPTR_t_DelayTimeToggle_KeOPTR_t_DelayTimeToggle: accessed-parameter=KeOPTR_t_DelayTimeToggle.KeOPTR_t_DelayTimeToggle
            CALPRM_KeOPTR_t_RGS_Delay_KeOPTR_t_RGS_Delay: accessed-parameter=KeOPTR_t_RGS_Delay.KeOPTR_t_RGS_Delay
            CALPRM_KeOPTR_t_RGS_DelayTimeNTurb_KeOPTR_t_RGS_DelayTimeNTurb: accessed-parameter=KeOPTR_t_RGS_DelayTimeNTurb.KeOPTR_t_RGS_DelayTimeNTurb
            CALPRM_KtOPTR_M_P2ZeroIdle_BrkTrqThres_KtOPTR_M_P2ZeroIdle_BrkTrqThres: accessed-parameter=KtOPTR_M_P2ZeroIdle_BrkTrqThres.KtOPTR_M_P2ZeroIdle_BrkTrqThres
            CALPRM_KtOPTR_n_P2IdleSpd_KtOPTR_n_P2IdleSpd: accessed-parameter=KtOPTR_n_P2IdleSpd.KtOPTR_n_P2IdleSpd
            CALPRM_KxOPTR_M_P2ZeroIdle_BrkTrqThres_KxOPTR_M_P2ZeroIdle_BrkTrqThres: accessed-parameter=KxOPTR_M_P2ZeroIdle_BrkTrqThres.KxOPTR_M_P2ZeroIdle_BrkTrqThres
            CALPRM_KxOPTR_n_P2IdleSpd_KxOPTR_n_P2IdleSpd: accessed-parameter=KxOPTR_n_P2IdleSpd.KxOPTR_n_P2IdleSpd
          read-local-variables:
            access RV_DsrdRngSt_write_IRV: accessed-variable=DsrdRngSt_write_IRV
            access RV_ShftEfftRdctn_write_IRV: accessed-variable=ShftEfftRdctn_write_IRV
            access RV_ShftEfft_N4H_write_IRV: accessed-variable=ShftEfft_N4H_write_IRV
          written-local-variables:
            14 x access:
              WV_EnblTCMReqL_write_IRV: accessed-variable=EnblTCMReqL_write_IRV
              WV_NTurb_ActGr_write_IRV: accessed-variable=NTurb_ActGr_write_IRV
              WV_NTurb_Virt_write_IRV: accessed-variable=NTurb_Virt_write_IRV
              WV_Nti_Max_write_IRV: accessed-variable=Nti_Max_write_IRV
              WV_Nti_Min_write_IRV: accessed-variable=Nti_Min_write_IRV
              WV_PS_write_IRV: accessed-variable=PS_write_IRV
              WV_RegenShiftMapRqst_write_IRV: accessed-variable=RegenShiftMapRqst_write_IRV
              WV_S2H_write_IRV: accessed-variable=S2H_write_IRV
              WV_ShiftToN_write_IRV: accessed-variable=ShiftToN_write_IRV
              WV_StgcMaxGear_NVH_write_IRV: accessed-variable=StgcMaxGear_NVH_write_IRV
              WV_TransMin_write_IRV: accessed-variable=TransMin_write_IRV
              WV_VeOHSR_e_ILEState_write_IRV: accessed-variable=VeOHSR_e_ILEState_write_IRV
              WV_VeOHSR_n_IdleSpdBlended_write_IRV: accessed-variable=VeOHSR_n_IdleSpdBlended_write_IRV
              WV_dSOC_write_IRV: accessed-variable=dSOC_write_IRV
        OHSR_MedTED
          data-receive-point-by-arguments:
            80 x access:
              IN_VaOSMR_d_FinalAllwdDsrd_Value: accessed-variable=VaOSMR_d_FinalAllwdDsrd.Value
              IN_VaOSMR_d_FinalAllwdFxdGr_Value: accessed-variable=VaOSMR_d_FinalAllwdFxdGr.Value
              IN_VaOSMR_d_FinalAllwdOpt_Value: accessed-variable=VaOSMR_d_FinalAllwdOpt.Value
              IN_VaOSMR_n_NTurb_FromNo_Value: accessed-variable=VaOSMR_n_NTurb_FromNo.Value
              IN_VaSCOR_P_EngPwrLoss_MA_Value: accessed-variable=VaSCOR_P_EngPwrLoss_MA.Value
              IN_VaSCOR_P_EngPwrLoss_MB_Value: accessed-variable=VaSCOR_P_EngPwrLoss_MB.Value
              IN_VaSCOR_P_EngPwrLoss_N_Value: accessed-variable=VaSCOR_P_EngPwrLoss_N.Value
              IN_VaSCOR_n_C1SlipSpdDsrdN_Value: accessed-variable=VaSCOR_n_C1SlipSpdDsrdN.Value
              IN_VaSCOR_n_C2SlipSpdDsrdN_Value: accessed-variable=VaSCOR_n_C2SlipSpdDsrdN.Value
              IN_VaSCOR_n_InputSpeedDsrdMA_Value: accessed-variable=VaSCOR_n_InputSpeedDsrdMA.Value
              IN_VaSCOR_n_InputSpeedDsrdMB_Value: accessed-variable=VaSCOR_n_InputSpeedDsrdMB.Value
              IN_VaSCOR_n_InputSpeedDsrdN_Value: accessed-variable=VaSCOR_n_InputSpeedDsrdN.Value
              IN_VaSCOR_n_MtrBSpdDsrdN_Value: accessed-variable=VaSCOR_n_MtrBSpdDsrdN.Value
              IN_VaSCOR_n_StgcNiMin_MA_Value: accessed-variable=VaSCOR_n_StgcNiMin_MA.Value
              IN_VaSCOR_n_StgcNiMin_MB_Value: accessed-variable=VaSCOR_n_StgcNiMin_MB.Value
              IN_VaSCOR_n_StgcNiMin_N_Value: accessed-variable=VaSCOR_n_StgcNiMin_N.Value
              IN_VeAPSR_Pct_AccelPedalEffPosition_Value: accessed-variable=VeAPSR_Pct_AccelPedalEffPosition.Value
              IN_VeBPCR_Pct_HV_BatPackSOC_Arb_Value: accessed-variable=VeBPCR_Pct_HV_BatPackSOC_Arb.Value
              IN_VeDTRR_e_SumFWIDFst_Value: accessed-variable=VeDTRR_e_SumFWIDFst.Value
              IN_VeENGR_T_CatalystTemp_Value: accessed-variable=VeENGR_T_CatalystTemp.Value
              IN_VeEOCR_b_ColdCtrl_Raw_Value: accessed-variable=VeEOCR_b_ColdCtrl_Raw.Value
              IN_VeESPR_b_TCMEngSpdReqActive_Value: accessed-variable=VeESPR_b_TCMEngSpdReqActive.Value
              IN_VeESPR_n_EngSpdMaxLim_Value: accessed-variable=VeESPR_n_EngSpdMaxLim.Value
              IN_VeESPR_n_EngSpdMinLim_Value: accessed-variable=VeESPR_n_EngSpdMinLim.Value
              IN_VeESPR_n_TCMEngSpdReq_Value: accessed-variable=VeESPR_n_TCMEngSpdReq.Value
              IN_VeESSR_e_EngStartStopSt_Value: accessed-variable=VeESSR_e_EngStartStopSt.Value
              IN_VeFWDR_e_Tcase_Stat_Value: accessed-variable=VeFWDR_e_Tcase_Stat.Value
              IN_VeHSER_e_RngEqnSel_Value: accessed-variable=VeHSER_e_RngEqnSel.Value
              IN_VeHSER_e_RngSt_Value: accessed-variable=VeHSER_e_RngSt.Value
              IN_VeMSPR_n_MtrB_Spd_Value: accessed-variable=VeMSPR_n_MtrB_Spd.Value
              IN_VeMSPR_n_P2SpdControl_TgtSpd_Value: accessed-variable=VeMSPR_n_P2SpdControl_TgtSpd.Value
              IN_VeOSMR_b_EngOffAllwdOpt_Value: accessed-variable=VeOSMR_b_EngOffAllwdOpt.Value
              IN_VeOSMR_b_ServEngOffReq_Actv_Value: accessed-variable=VeOSMR_b_ServEngOffReq_Actv.Value
              IN_VeOSMR_d_FnctnEnblReg_Value: accessed-variable=VeOSMR_d_FnctnEnblReg.Value
              IN_VeOSMR_d_ManualAllowedMA_Value: accessed-variable=VeOSMR_d_ManualAllowedMA.Value
              IN_VeOSMR_d_ManualAllowedMB_Value: accessed-variable=VeOSMR_d_ManualAllowedMB.Value
              IN_VeOSMR_d_ManualAllowedN_Value: accessed-variable=VeOSMR_d_ManualAllowedN.Value
              IN_VeOSMR_e_ActualGear_Value: accessed-variable=VeOSMR_e_ActualGear.Value
              IN_VeOSMR_e_SteadyTransSt_Value: accessed-variable=VeOSMR_e_SteadyTransSt.Value
              IN_VeOSMR_e_TargetGear_Value: accessed-variable=VeOSMR_e_TargetGear.Value
              IN_VeOSMR_i_DrvPrg_AutoRevMaxType_Value: accessed-variable=VeOSMR_i_DrvPrg_AutoRevMaxType.Value
              IN_VeOSMR_n_InputSpdMaxMAAct_Value: accessed-variable=VeOSMR_n_InputSpdMaxMAAct.Value
              IN_VeOSMR_n_InputSpdMaxMATgt_Value: accessed-variable=VeOSMR_n_InputSpdMaxMATgt.Value
              IN_VeOSMR_n_InputSpdMaxMBAct_Value: accessed-variable=VeOSMR_n_InputSpdMaxMBAct.Value
              IN_VeOSMR_n_InputSpdMaxMBTgt_Value: accessed-variable=VeOSMR_n_InputSpdMaxMBTgt.Value
              IN_VeOSMR_n_InputSpdMaxNAct_Value: accessed-variable=VeOSMR_n_InputSpdMaxNAct.Value
              IN_VeOSMR_n_InputSpdMaxNTgt_Value: accessed-variable=VeOSMR_n_InputSpdMaxNTgt.Value
              IN_VeOSMR_n_InputSpdMinMAAct_Value: accessed-variable=VeOSMR_n_InputSpdMinMAAct.Value
              IN_VeOSMR_n_InputSpdMinMATgt_Value: accessed-variable=VeOSMR_n_InputSpdMinMATgt.Value
              IN_VeOSMR_n_InputSpdMinMBAct_Value: accessed-variable=VeOSMR_n_InputSpdMinMBAct.Value
              IN_VeOSMR_n_InputSpdMinMBTgt_Value: accessed-variable=VeOSMR_n_InputSpdMinMBTgt.Value
              IN_VeOSMR_n_InputSpdMinNAct_Value: accessed-variable=VeOSMR_n_InputSpdMinNAct.Value
              IN_VeOSMR_n_InputSpdMinNTgt_Value: accessed-variable=VeOSMR_n_InputSpdMinNTgt.Value
              IN_VeOSMR_n_MtrBSpd_Max_Value: accessed-variable=VeOSMR_n_MtrBSpd_Max.Value
              IN_VeOSMR_n_MtrBSpd_Min_Value: accessed-variable=VeOSMR_n_MtrBSpd_Min.Value
              IN_VeOSMR_n_TransMinEngSpd_Value: accessed-variable=VeOSMR_n_TransMinEngSpd.Value
              IN_VeOSMR_n_TransOutSpd_Value: accessed-variable=VeOSMR_n_TransOutSpd.Value
              IN_VeRTMR_e_ClutchLrnType_Value: accessed-variable=VeRTMR_e_ClutchLrnType.Value
              IN_VeRTMR_e_HybTransCmndSt_Value: accessed-variable=VeRTMR_e_HybTransCmndSt.Value
              IN_VeRTMR_n_TransInputSpd_Value: accessed-variable=VeRTMR_n_TransInputSpd.Value
              IN_VeSCOR_P_FCDsrdPwr_Value: accessed-variable=VeSCOR_P_FCDsrdPwr.Value
              IN_VeSCOR_Pct_TtlPdlChange_Value: accessed-variable=VeSCOR_Pct_TtlPdlChange.Value
              IN_VeSCOR_b_DsrdRngOnAllwd_Value: accessed-variable=VeSCOR_b_DsrdRngOnAllwd.Value
              IN_VeSCOR_b_DsrdRngStAllwd_Value: accessed-variable=VeSCOR_b_DsrdRngStAllwd.Value
              IN_VeSCOR_b_ReqFC_Value: accessed-variable=VeSCOR_b_ReqFC.Value
              IN_VeSCOR_b_TLC_Req_Value: accessed-variable=VeSCOR_b_TLC_Req.Value
              IN_VeSCOR_e_RngDsrd_Value: accessed-variable=VeSCOR_e_RngDsrd.Value
              IN_VeSCOR_e_RngDsrd_EngOn_Value: accessed-variable=VeSCOR_e_RngDsrd_EngOn.Value
              IN_VeSCOR_e_RngOpt_Value: accessed-variable=VeSCOR_e_RngOpt.Value
              IN_VeSCOR_e_SGrDsrd_Value: accessed-variable=VeSCOR_e_SGrDsrd.Value
              IN_VeSCOR_e_SGrDsrd_EngOn_Value: accessed-variable=VeSCOR_e_SGrDsrd_EngOn.Value, variation-point={short-label=vpIN_VeSCOR_e_SGrDsrd_EngOn_Value, sw-syscond=1}
              IN_VeSTRR_b_EngOffAllowed_Value: accessed-variable=VeSTRR_b_EngOffAllowed.Value
              IN_VeTFTR_T_TransOilTemp_Value: accessed-variable=VeTFTR_T_TransOilTemp.Value
              IN_VeTISR_n_InputSpeed_Value: accessed-variable=VeTISR_n_InputSpeed.Value
              IN_VeTISR_n_TransMinInputSpd_Value: accessed-variable=VeTISR_n_TransMinInputSpd.Value
              IN_VeTRNR_e_ActualGear_Value: accessed-variable=VeTRNR_e_ActualGear.Value
              IN_VeTRNR_e_TargetGear_Value: accessed-variable=VeTRNR_e_TargetGear.Value
              IN_VeVSDR_n_NTurb_Value: accessed-variable=VeVSDR_n_NTurb.Value
              IN_VeVTVR_M_LoadTorqFront_Opt_Value: accessed-variable=VeVTVR_M_LoadTorqFront_Opt.Value
              IN_VeVTVR_e_TrqArb_Value: accessed-variable=VeVTVR_e_TrqArb.Value
          data-send-points:
            21 x access:
              OUT_VeOHSR_b_EngOnDsrdOpt_Value: accessed-variable=VeOHSR_b_EngOnDsrdOpt.Value
              OUT_VeOHSR_e_SGrDsrd_Value: accessed-variable=VeOHSR_e_SGrDsrd.Value
              OUT_VeOHSR_e_SGrDsrd_EngOn_Value: accessed-variable=VeOHSR_e_SGrDsrd_EngOn.Value
              OUT_VeOHSR_b_EngDsrd_Value: accessed-variable=VeOHSR_b_EngDsrd.Value
              OUT_VaOHSR_n_NtiMaxPerStgcRngSt_Value: accessed-variable=VaOHSR_n_NtiMaxPerStgcRngSt.Value
              OUT_VaOHSR_n_NtiMinPerStgcRngSt_Value: accessed-variable=VaOHSR_n_NtiMinPerStgcRngSt.Value
              OUT_VeOHSR_e_SGrDsrd_GSI_Value: accessed-variable=VeOHSR_e_SGrDsrd_GSI.Value
              OUT_VeOHSR_b_EnaGSI_Value: accessed-variable=VeOHSR_b_EnaGSI.Value
              OUT_VeOHSR_b_ServEngOff_StgcInhb_Value: accessed-variable=VeOHSR_b_ServEngOff_StgcInhb.Value
              OUT_VeOHSR_n_InputSpeedDsrdM3_Value: accessed-variable=VeOHSR_n_InputSpeedDsrdM3.Value
              OUT_VeOHSR_n_MtrBSpeedDsrd_Value: accessed-variable=VeOHSR_n_MtrBSpeedDsrd.Value
              OUT_VeOHSR_n_TransMinEngSpd_Value: accessed-variable=VeOHSR_n_TransMinEngSpd.Value
              OUT_VeOHSR_n_InputSpeedDsrdM1_Value: accessed-variable=VeOHSR_n_InputSpeedDsrdM1.Value
              OUT_VeOHSR_n_InputSpeedDsrdM2_Value: accessed-variable=VeOHSR_n_InputSpeedDsrdM2.Value
              OUT_VeOHSR_n_InputSpeedDsrdN_Value: accessed-variable=VeOHSR_n_InputSpeedDsrdN.Value
              OUT_VeOHSR_e_RngDsrd_Value: accessed-variable=VeOHSR_e_RngDsrd.Value
              OUT_VeOHSR_b_RegenShiftMap_Rqst_Value: accessed-variable=VeOHSR_b_RegenShiftMap_Rqst.Value
              OUT_VeOHSR_b_DsrdRngOnAllwd_Value: accessed-variable=VeOHSR_b_DsrdRngOnAllwd.Value
              OUT_VeOHSR_b_DsrdRngStAllwd_Value: accessed-variable=VeOHSR_b_DsrdRngStAllwd.Value
              OUT_VeOHSR_b_ReqFC_Value: accessed-variable=VeOHSR_b_ReqFC.Value
              OUT_VeOHSR_P_FCDsrdPwr_Value: accessed-variable=VeOHSR_P_FCDsrdPwr.Value
          read-local-variables:
            12 x access:
              RV_EnblTCMReqL_write_IRV: accessed-variable=EnblTCMReqL_write_IRV
              RV_NTurb_ActGr_write_IRV: accessed-variable=NTurb_ActGr_write_IRV
              RV_NTurb_Virt_write_IRV: accessed-variable=NTurb_Virt_write_IRV
              RV_Nti_Max_write_IRV: accessed-variable=Nti_Max_write_IRV
              RV_Nti_Min_write_IRV: accessed-variable=Nti_Min_write_IRV
              RV_PS_write_IRV: accessed-variable=PS_write_IRV
              RV_RegenShiftMapRqst_write_IRV: accessed-variable=RegenShiftMapRqst_write_IRV
              RV_S2H_write_IRV: accessed-variable=S2H_write_IRV
              RV_ShiftToN_write_IRV: accessed-variable=ShiftToN_write_IRV
              RV_TransMin_write_IRV: accessed-variable=TransMin_write_IRV
              RV_VeOHSR_e_ILEState_write_IRV: accessed-variable=VeOHSR_e_ILEState_write_IRV
              RV_VeOHSR_n_IdleSpdBlended_write_IRV: accessed-variable=VeOHSR_n_IdleSpdBlended_write_IRV
          written-local-variables:
            access WV_DsrdRngSt_write_IRV: accessed-variable=DsrdRngSt_write_IRV
            access WV_ShftEfftRdctn_write_IRV: accessed-variable=ShftEfftRdctn_write_IRV
            access WV_ShftEfft_N4H_write_IRV: accessed-variable=ShftEfft_N4H_write_IRV
      15 x variation point proxy, all with category=CONDITION, condition-access=0:
        Variant_OHSR_FUNC_PxPy_1
        Variant_OHSR_FUNC_PxPy_11
        Variant_OHSR_FUNC_PxPy_13
        Variant_OHSR_FUNC_PxPy_15
        Variant_OHSR_FUNC_PxPy_17
        Variant_OHSR_FUNC_PxPy_19
        Variant_OHSR_FUNC_PxPy_21
        Variant_OHSR_FUNC_PxPy_23
        Variant_OHSR_FUNC_PxPy_25
        Variant_OHSR_FUNC_PxPy_27
        Variant_OHSR_FUNC_PxPy_29
        Variant_OHSR_FUNC_PxPy_3
        Variant_OHSR_FUNC_PxPy_5
        Variant_OHSR_FUNC_PxPy_7
        Variant_OHSR_FUNC_PxPy_9
